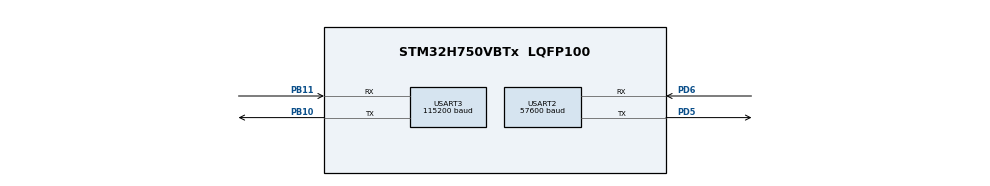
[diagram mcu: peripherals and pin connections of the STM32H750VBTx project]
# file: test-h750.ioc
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Mcu.Family=STM32H7
Mcu.Name=STM32H750VBTx
Mcu.Package=LQFP100
NVIC.PriorityGroup=NVIC_PRIORITYGROUP_4
NVIC.USART3_IRQn=true\:0\:0\:false\:false\:true\:true\:true\:true
PB10.Mode=Asynchronous
PB10.Signal=USART3_TX
PB11.Mode=Asynchronous
PB11.Signal=USART3_RX
PD5.Mode=Asynchronous
PD5.Signal=USART2_TX
PD6.Mode=Asynchronous
PD6.Signal=USART2_RX
PH0-OSC_IN\ (PH0).Mode=HSE-External-Oscillator
PH0-OSC_IN\ (PH0).Signal=RCC_OSC_IN
PH1-OSC_OUT\ (PH1).Mode=HSE-External-Oscillator
PH1-OSC_OUT\ (PH1).Signal=RCC_OSC_OUT
ProjectManager.HeapSize=0x200
ProjectManager.StackSize=0x400
ProjectManager.TargetToolchain=STM32CubeIDE
RCC.ADCFreq_Value=50390625
RCC.APB1Freq_Value=120000000
RCC.APB2Freq_Value=120000000
RCC.APB3Freq_Value=120000000
RCC.APB4Freq_Value=120000000
RCC.CortexFreq_Value=480000000
RCC.D1PPRE=RCC_APB3_DIV2
RCC.D2PPRE1=RCC_APB1_DIV2
RCC.D2PPRE2=RCC_APB2_DIV2
RCC.D3PPRE=RCC_APB4_DIV2
RCC.DIVM1=5
RCC.DIVM3=25
RCC.DIVN1=192
RCC.DIVN3=194
RCC.HCLKFreq_Value=240000000
RCC.HPRE=RCC_HCLK_DIV2
RCC.PLLSourceVirtual=RCC_PLLSOURCE_HSE
RCC.SYSCLKFreq_VALUE=480000000
RCC.SYSCLKSource=RCC_SYSCLKSOURCE_PLLCLK
RCC.USART234578CLockSelection=RCC_USART234578CLKSOURCE_PLL3
RCC.USBFreq_Value=480000000
USART2.BaudRate=57600
USART2.Parity=PARITY_EVEN
USART2.VirtualMode-Asynchronous=VM_ASYNC
USART3.BaudRate=115200
USART3.Parity=PARITY_EVEN
USART3.VirtualMode-Asynchronous=VM_ASYNC
board=custom

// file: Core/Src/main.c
/* USER CODE BEGIN Header */
/**
  ******************************************************************************
  * @file           : main.c
  * @brief          : Main program body
  ******************************************************************************
  * @attention
  *
  * Copyright (c) 2022 STMicroelectronics.
  * All rights reserved.
  *
  * This software is licensed under terms that can be found in the LICENSE file
  * in the root directory of this software component.
  * If no LICENSE file comes with this software, it is provided AS-IS.
  *
  ******************************************************************************
  */
/* USER CODE END Header */
#include "main.h"

UART_HandleTypeDef huart2;
UART_HandleTypeDef huart3;

void SystemClock_Config(void);
void PeriphCommonClock_Config(void);
static void MX_GPIO_Init(void);
static void MX_USART2_UART_Init(void);
static void MX_USART3_UART_Init(void);

int main(void)
{

  /* MCU Configuration--------------------------------------------------------*/

  /* Reset of all peripherals, Initializes the Flash interface and the Systick. */
  HAL_Init();

  /* Configure the system clock */
  SystemClock_Config();

/* Configure the peripherals common clocks */
  PeriphCommonClock_Config();

  /* Initialize all configured peripherals */
  MX_GPIO_Init();
  MX_USART2_UART_Init();
  MX_USART3_UART_Init();

  static const char message[] = "hello, world. this is a test";
  static const int message_len = sizeof (message);
  static const int UART_TIMEOUT = 100;

  /* Infinite loop */
  /* USER CODE BEGIN WHILE */
  while (1)
  {
	  HAL_Delay(1000);
	  HAL_UART_Transmit(&huart3, message, message_len, UART_TIMEOUT);
    /* USER CODE END WHILE */

  }
}

void SystemClock_Config(void)
{
  RCC_OscInitTypeDef RCC_OscInitStruct = {0};
  RCC_ClkInitTypeDef RCC_ClkInitStruct = {0};

  /** Supply configuration update enable
  */
  HAL_PWREx_ConfigSupply(PWR_LDO_SUPPLY);

  /** Configure the main internal regulator output voltage
  */
  __HAL_PWR_VOLTAGESCALING_CONFIG(PWR_REGULATOR_VOLTAGE_SCALE1);

  while(!__HAL_PWR_GET_FLAG(PWR_FLAG_VOSRDY)) {}

  __HAL_RCC_SYSCFG_CLK_ENABLE();
  __HAL_PWR_VOLTAGESCALING_CONFIG(PWR_REGULATOR_VOLTAGE_SCALE0);

  while(!__HAL_PWR_GET_FLAG(PWR_FLAG_VOSRDY)) {}

  /** Macro to configure the PLL clock source
  */
  __HAL_RCC_PLL_PLLSOURCE_CONFIG(RCC_PLLSOURCE_HSE);

  /** Initializes the RCC Oscillators according to the specified parameters
  * in the RCC_OscInitTypeDef structure.
  */
  RCC_OscInitStruct.OscillatorType = RCC_OSCILLATORTYPE_HSE;
  RCC_OscInitStruct.HSEState = RCC_HSE_ON;
  RCC_OscInitStruct.PLL.PLLState = RCC_PLL_ON;
  RCC_OscInitStruct.PLL.PLLSource = RCC_PLLSOURCE_HSE;
  RCC_OscInitStruct.PLL.PLLM = 5;
  RCC_OscInitStruct.PLL.PLLN = 192;
  RCC_OscInitStruct.PLL.PLLP = 2;
  RCC_OscInitStruct.PLL.PLLQ = 2;
  RCC_OscInitStruct.PLL.PLLR = 2;
  RCC_OscInitStruct.PLL.PLLRGE = RCC_PLL1VCIRANGE_2;
  RCC_OscInitStruct.PLL.PLLVCOSEL = RCC_PLL1VCOWIDE;
  RCC_OscInitStruct.PLL.PLLFRACN = 0;
  if (HAL_RCC_OscConfig(&RCC_OscInitStruct) != HAL_OK)
  {
    Error_Handler();
  }

  /** Initializes the CPU, AHB and APB buses clocks
  */
  RCC_ClkInitStruct.ClockType = RCC_CLOCKTYPE_HCLK|RCC_CLOCKTYPE_SYSCLK
                              |RCC_CLOCKTYPE_PCLK1|RCC_CLOCKTYPE_PCLK2
                              |RCC_CLOCKTYPE_D3PCLK1|RCC_CLOCKTYPE_D1PCLK1;
  RCC_ClkInitStruct.SYSCLKSource = RCC_SYSCLKSOURCE_PLLCLK;
  RCC_ClkInitStruct.SYSCLKDivider = RCC_SYSCLK_DIV1;
  RCC_ClkInitStruct.AHBCLKDivider = RCC_HCLK_DIV2;
  RCC_ClkInitStruct.APB3CLKDivider = RCC_APB3_DIV2;
  RCC_ClkInitStruct.APB1CLKDivider = RCC_APB1_DIV2;
  RCC_ClkInitStruct.APB2CLKDivider = RCC_APB2_DIV2;
  RCC_ClkInitStruct.APB4CLKDivider = RCC_APB4_DIV2;

  if (HAL_RCC_ClockConfig(&RCC_ClkInitStruct, FLASH_LATENCY_4) != HAL_OK)
  {
    Error_Handler();
  }
}

void PeriphCommonClock_Config(void)
{
  RCC_PeriphCLKInitTypeDef PeriphClkInitStruct = {0};

  /** Initializes the peripherals clock
  */
  PeriphClkInitStruct.PeriphClockSelection = RCC_PERIPHCLK_USART2|RCC_PERIPHCLK_USART3;
  PeriphClkInitStruct.PLL3.PLL3M = 25;
  PeriphClkInitStruct.PLL3.PLL3N = 194;
  PeriphClkInitStruct.PLL3.PLL3P = 2;
  PeriphClkInitStruct.PLL3.PLL3Q = 2;
  PeriphClkInitStruct.PLL3.PLL3R = 2;
  PeriphClkInitStruct.PLL3.PLL3RGE = RCC_PLL3VCIRANGE_0;
  PeriphClkInitStruct.PLL3.PLL3VCOSEL = RCC_PLL3VCOWIDE;
  PeriphClkInitStruct.PLL3.PLL3FRACN = 0;
  PeriphClkInitStruct.Usart234578ClockSelection = RCC_USART234578CLKSOURCE_PLL3;
  if (HAL_RCCEx_PeriphCLKConfig(&PeriphClkInitStruct) != HAL_OK)
  {
    Error_Handler();
  }
}

static void MX_USART2_UART_Init(void)
{

  huart2.Instance = USART2;
  huart2.Init.BaudRate = 57600;
  huart2.Init.WordLength = UART_WORDLENGTH_8B;
  huart2.Init.StopBits = UART_STOPBITS_1;
  huart2.Init.Parity = UART_PARITY_EVEN;
  huart2.Init.Mode = UART_MODE_TX_RX;
  huart2.Init.HwFlowCtl = UART_HWCONTROL_NONE;
  huart2.Init.OverSampling = UART_OVERSAMPLING_16;
  huart2.Init.OneBitSampling = UART_ONE_BIT_SAMPLE_DISABLE;
  huart2.Init.ClockPrescaler = UART_PRESCALER_DIV1;
  huart2.AdvancedInit.AdvFeatureInit = UART_ADVFEATURE_NO_INIT;
  if (HAL_UART_Init(&huart2) != HAL_OK)
  {
    Error_Handler();
  }
  if (HAL_UARTEx_SetTxFifoThreshold(&huart2, UART_TXFIFO_THRESHOLD_1_8) != HAL_OK)
  {
    Error_Handler();
  }
  if (HAL_UARTEx_SetRxFifoThreshold(&huart2, UART_RXFIFO_THRESHOLD_1_8) != HAL_OK)
  {
    Error_Handler();
  }
  if (HAL_UARTEx_DisableFifoMode(&huart2) != HAL_OK)
  {
    Error_Handler();
  }

}

static void MX_USART3_UART_Init(void)
{

  huart3.Instance = USART3;
  huart3.Init.BaudRate = 115200;
  huart3.Init.WordLength = UART_WORDLENGTH_8B;
  huart3.Init.StopBits = UART_STOPBITS_1;
  huart3.Init.Parity = UART_PARITY_EVEN;
  huart3.Init.Mode = UART_MODE_TX_RX;
  huart3.Init.HwFlowCtl = UART_HWCONTROL_NONE;
  huart3.Init.OverSampling = UART_OVERSAMPLING_16;
  huart3.Init.OneBitSampling = UART_ONE_BIT_SAMPLE_DISABLE;
  huart3.Init.ClockPrescaler = UART_PRESCALER_DIV1;
  huart3.AdvancedInit.AdvFeatureInit = UART_ADVFEATURE_NO_INIT;
  if (HAL_UART_Init(&huart3) != HAL_OK)
  {
    Error_Handler();
  }
  if (HAL_UARTEx_SetTxFifoThreshold(&huart3, UART_TXFIFO_THRESHOLD_1_8) != HAL_OK)
  {
    Error_Handler();
  }
  if (HAL_UARTEx_SetRxFifoThreshold(&huart3, UART_RXFIFO_THRESHOLD_1_8) != HAL_OK)
  {
    Error_Handler();
  }
  if (HAL_UARTEx_DisableFifoMode(&huart3) != HAL_OK)
  {
    Error_Handler();
  }

}

static void MX_GPIO_Init(void)
{

  /* GPIO Ports Clock Enable */
  __HAL_RCC_GPIOH_CLK_ENABLE();
  __HAL_RCC_GPIOB_CLK_ENABLE();
  __HAL_RCC_GPIOD_CLK_ENABLE();

}

void Error_Handler(void)
{
  __disable_irq();
  while (1)
  {
  }
}
